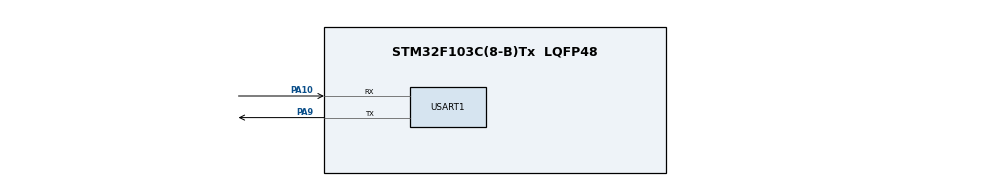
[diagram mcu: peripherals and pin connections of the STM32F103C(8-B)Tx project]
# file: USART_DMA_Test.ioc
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Dma.Request0=USART1_RX
Dma.Request1=USART1_TX
Dma.USART1_RX.0.Direction=DMA_PERIPH_TO_MEMORY
Dma.USART1_RX.0.Instance=DMA1_Channel5
Dma.USART1_RX.0.MemDataAlignment=DMA_MDATAALIGN_BYTE
Dma.USART1_RX.0.MemInc=DMA_MINC_ENABLE
Dma.USART1_RX.0.Mode=DMA_NORMAL
Dma.USART1_RX.0.PeriphDataAlignment=DMA_PDATAALIGN_BYTE
Dma.USART1_RX.0.PeriphInc=DMA_PINC_DISABLE
Dma.USART1_RX.0.Priority=DMA_PRIORITY_LOW
Dma.USART1_TX.1.Direction=DMA_MEMORY_TO_PERIPH
Dma.USART1_TX.1.Instance=DMA1_Channel4
Dma.USART1_TX.1.MemDataAlignment=DMA_MDATAALIGN_BYTE
Dma.USART1_TX.1.MemInc=DMA_MINC_ENABLE
Dma.USART1_TX.1.Mode=DMA_NORMAL
Dma.USART1_TX.1.PeriphDataAlignment=DMA_PDATAALIGN_BYTE
Dma.USART1_TX.1.PeriphInc=DMA_PINC_DISABLE
Dma.USART1_TX.1.Priority=DMA_PRIORITY_LOW
Mcu.Family=STM32F1
Mcu.Name=STM32F103C(8-B)Tx
Mcu.Package=LQFP48
NVIC.DMA1_Channel4_IRQn=true\:3\:0\:true\:false\:true\:false\:true\:true
NVIC.DMA1_Channel5_IRQn=true\:3\:0\:true\:false\:true\:false\:true\:true
NVIC.PriorityGroup=NVIC_PRIORITYGROUP_4
NVIC.USART1_IRQn=true\:1\:0\:true\:false\:true\:true\:true\:true
PA10.Mode=Asynchronous
PA10.Signal=USART1_RX
PA9.Mode=Asynchronous
PA9.Signal=USART1_TX
PD0-OSC_IN.Mode=HSE-External-Oscillator
PD0-OSC_IN.Signal=RCC_OSC_IN
PD1-OSC_OUT.Mode=HSE-External-Oscillator
PD1-OSC_OUT.Signal=RCC_OSC_OUT
ProjectManager.HeapSize=0x200
ProjectManager.StackSize=0x400
ProjectManager.TargetToolchain=MDK-ARM V5.32
RCC.APB1Freq_Value=8000000
RCC.APB2Freq_Value=8000000
RTC.Format=RTC_FORMAT_BIN
USART1.VirtualMode=VM_ASYNC
VP_RTC_VS_RTC_Activate.Mode=RTC_Enabled
VP_RTC_VS_RTC_Calendar.Mode=RTC_Calendar
VP_SYS_VS_ND.Mode=No_Debug
board=custom

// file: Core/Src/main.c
/* USER CODE BEGIN Header */
/**
  ******************************************************************************
  * @file           : main.c
  * @brief          : Main program body
  ******************************************************************************
  * @attention
  *
  * Copyright (c) 2023 STMicroelectronics.
  * All rights reserved.
  *
  * This software is licensed under terms that can be found in the LICENSE file
  * in the root directory of this software component.
  * If no LICENSE file comes with this software, it is provided AS-IS.
  *
  ******************************************************************************
  */
/* USER CODE END Header */
#include "main.h"

/* USER CODE BEGIN Includes */
#include <stdio.h>
#include <string.h>
#include <stdarg.h>
/* USER CODE END Includes */

RTC_HandleTypeDef hrtc;

UART_HandleTypeDef huart1;
DMA_HandleTypeDef hdma_usart1_rx;
DMA_HandleTypeDef hdma_usart1_tx;

/* USER CODE BEGIN PV */
uint8_t rx_buffer[128];
RTC_TimeTypeDef time;
RTC_DateTypeDef date;
/* USER CODE END PV */

void SystemClock_Config(void);
static void MX_GPIO_Init(void);
static void MX_DMA_Init(void);
static void MX_RTC_Init(void);
static void MX_USART1_UART_Init(void);

/* USER CODE BEGIN 0 */
char  DebugBuf[64];
void Debug(char *p,...)
{
	va_list ap;
	va_start(ap,p);
	vsprintf(DebugBuf,p,ap);
	va_end(ap);
	HAL_UART_Transmit(&huart1,(uint8_t *)DebugBuf,strlen(DebugBuf),50);
}

/* USER CODE END 0 */

int main(void)
{

  /* MCU Configuration--------------------------------------------------------*/

  /* Reset of all peripherals, Initializes the Flash interface and the Systick. */
  HAL_Init();

  /* Configure the system clock */
  SystemClock_Config();

  /* Initialize all configured peripherals */
  MX_GPIO_Init();
  MX_DMA_Init();
  MX_RTC_Init();
  MX_USART1_UART_Init();

  /* Infinite loop */
  while (1)
  {
		HAL_RTC_GetTime(&hrtc,&time,RTC_FORMAT_BIN);
		Debug("%02d:%02d:%02d\n%02d-%02d-%02d %02d",time.Hours,time.Minutes,time.Seconds,date.Year,date.Month,date.Date,date.WeekDay);
		HAL_Delay(1000);
  }
}

void SystemClock_Config(void)
{
  RCC_OscInitTypeDef RCC_OscInitStruct = {0};
  RCC_ClkInitTypeDef RCC_ClkInitStruct = {0};
  RCC_PeriphCLKInitTypeDef PeriphClkInit = {0};

  /** Initializes the RCC Oscillators according to the specified parameters
  * in the RCC_OscInitTypeDef structure.
  */
  RCC_OscInitStruct.OscillatorType = RCC_OSCILLATORTYPE_HSI|RCC_OSCILLATORTYPE_LSI;
  RCC_OscInitStruct.HSIState = RCC_HSI_ON;
  RCC_OscInitStruct.HSICalibrationValue = RCC_HSICALIBRATION_DEFAULT;
  RCC_OscInitStruct.LSIState = RCC_LSI_ON;
  RCC_OscInitStruct.PLL.PLLState = RCC_PLL_NONE;
  if (HAL_RCC_OscConfig(&RCC_OscInitStruct) != HAL_OK)
  {
    Error_Handler();
  }

  /** Initializes the CPU, AHB and APB buses clocks
  */
  RCC_ClkInitStruct.ClockType = RCC_CLOCKTYPE_HCLK|RCC_CLOCKTYPE_SYSCLK
                              |RCC_CLOCKTYPE_PCLK1|RCC_CLOCKTYPE_PCLK2;
  RCC_ClkInitStruct.SYSCLKSource = RCC_SYSCLKSOURCE_HSI;
  RCC_ClkInitStruct.AHBCLKDivider = RCC_SYSCLK_DIV1;
  RCC_ClkInitStruct.APB1CLKDivider = RCC_HCLK_DIV1;
  RCC_ClkInitStruct.APB2CLKDivider = RCC_HCLK_DIV1;

  if (HAL_RCC_ClockConfig(&RCC_ClkInitStruct, FLASH_LATENCY_0) != HAL_OK)
  {
    Error_Handler();
  }
  PeriphClkInit.PeriphClockSelection = RCC_PERIPHCLK_RTC;
  PeriphClkInit.RTCClockSelection = RCC_RTCCLKSOURCE_LSI;
  if (HAL_RCCEx_PeriphCLKConfig(&PeriphClkInit) != HAL_OK)
  {
    Error_Handler();
  }
}

static void MX_RTC_Init(void)
{

  RTC_TimeTypeDef sTime = {0};
  RTC_DateTypeDef DateToUpdate = {0};

  /** Initialize RTC Only
  */
  hrtc.Instance = RTC;
  hrtc.Init.AsynchPrediv = RTC_AUTO_1_SECOND;
  hrtc.Init.OutPut = RTC_OUTPUTSOURCE_ALARM;
  if (HAL_RTC_Init(&hrtc) != HAL_OK)
  {
    Error_Handler();
  }

  /** Initialize RTC and set the Time and Date
  */
  sTime.Hours = 0;
  sTime.Minutes = 0;
  sTime.Seconds = 0;

  if (HAL_RTC_SetTime(&hrtc, &sTime, RTC_FORMAT_BIN) != HAL_OK)
  {
    Error_Handler();
  }
  DateToUpdate.WeekDay = RTC_WEEKDAY_MONDAY;
  DateToUpdate.Month = RTC_MONTH_JANUARY;
  DateToUpdate.Date = 1;
  DateToUpdate.Year = 0;

  if (HAL_RTC_SetDate(&hrtc, &DateToUpdate, RTC_FORMAT_BIN) != HAL_OK)
  {
    Error_Handler();
  }

}

static void MX_USART1_UART_Init(void)
{

  huart1.Instance = USART1;
  huart1.Init.BaudRate = 115200;
  huart1.Init.WordLength = UART_WORDLENGTH_8B;
  huart1.Init.StopBits = UART_STOPBITS_1;
  huart1.Init.Parity = UART_PARITY_NONE;
  huart1.Init.Mode = UART_MODE_TX_RX;
  huart1.Init.HwFlowCtl = UART_HWCONTROL_NONE;
  huart1.Init.OverSampling = UART_OVERSAMPLING_16;
  if (HAL_UART_Init(&huart1) != HAL_OK)
  {
    Error_Handler();
  }
  /* USER CODE BEGIN USART1_Init 2 */
	__HAL_UART_ENABLE_IT(&huart1,UART_IT_IDLE);

		HAL_UART_Receive_DMA(&huart1,rx_buffer,sizeof(rx_buffer));
  /* USER CODE END USART1_Init 2 */

}

static void MX_DMA_Init(void)
{

  /* DMA controller clock enable */
  __HAL_RCC_DMA1_CLK_ENABLE();

  /* DMA interrupt init */
  /* DMA1_Channel4_IRQn interrupt configuration */
  HAL_NVIC_SetPriority(DMA1_Channel4_IRQn, 3, 0);
  HAL_NVIC_EnableIRQ(DMA1_Channel4_IRQn);
  /* DMA1_Channel5_IRQn interrupt configuration */
  HAL_NVIC_SetPriority(DMA1_Channel5_IRQn, 3, 0);
  HAL_NVIC_EnableIRQ(DMA1_Channel5_IRQn);

}

static void MX_GPIO_Init(void)
{

  /* GPIO Ports Clock Enable */
  __HAL_RCC_GPIOD_CLK_ENABLE();
  __HAL_RCC_GPIOA_CLK_ENABLE();

}

void Error_Handler(void)
{
  __disable_irq();
  while (1)
  {
  }
}
